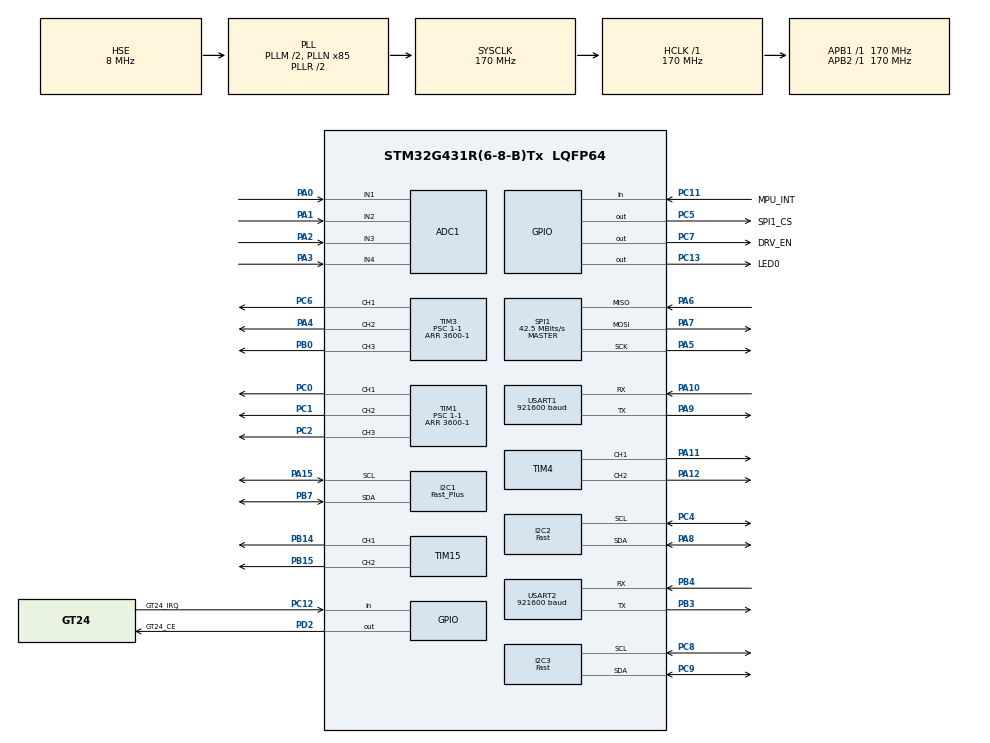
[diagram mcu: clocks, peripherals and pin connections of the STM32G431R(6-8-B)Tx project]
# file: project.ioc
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ADC1.Channel-0\#ChannelRegularConversion=ADC_CHANNEL_1
ADC1.Channel-1\#ChannelRegularConversion=ADC_CHANNEL_2
ADC1.Channel-2\#ChannelRegularConversion=ADC_CHANNEL_3
ADC1.Channel-3\#ChannelRegularConversion=ADC_CHANNEL_4
ADC1.GainCompensation=0
ADC1.NbrOfConversion=4
ADC1.NbrOfConversionFlag=1
ADC1.OffsetNumber-0\#ChannelRegularConversion=ADC_OFFSET_NONE
ADC1.OffsetNumber-1\#ChannelRegularConversion=ADC_OFFSET_NONE
ADC1.OffsetNumber-2\#ChannelRegularConversion=ADC_OFFSET_NONE
ADC1.OffsetNumber-3\#ChannelRegularConversion=ADC_OFFSET_NONE
ADC1.Rank-0\#ChannelRegularConversion=1
ADC1.Rank-1\#ChannelRegularConversion=2
ADC1.Rank-2\#ChannelRegularConversion=3
ADC1.Rank-3\#ChannelRegularConversion=4
ADC1.SamplingTime-0\#ChannelRegularConversion=ADC_SAMPLETIME_2CYCLES_5
ADC1.SamplingTime-1\#ChannelRegularConversion=ADC_SAMPLETIME_2CYCLES_5
ADC1.SamplingTime-2\#ChannelRegularConversion=ADC_SAMPLETIME_2CYCLES_5
ADC1.SamplingTime-3\#ChannelRegularConversion=ADC_SAMPLETIME_2CYCLES_5
ADC1.master=1
Dma.ADC1.0.Direction=DMA_PERIPH_TO_MEMORY
Dma.ADC1.0.EventEnable=DISABLE
Dma.ADC1.0.Instance=DMA1_Channel1
Dma.ADC1.0.MemDataAlignment=DMA_MDATAALIGN_WORD
Dma.ADC1.0.MemInc=DMA_MINC_ENABLE
Dma.ADC1.0.Mode=DMA_CIRCULAR
Dma.ADC1.0.PeriphDataAlignment=DMA_PDATAALIGN_WORD
Dma.ADC1.0.PeriphInc=DMA_PINC_DISABLE
Dma.ADC1.0.Polarity=HAL_DMAMUX_REQ_GEN_RISING
Dma.ADC1.0.Priority=DMA_PRIORITY_LOW
Dma.ADC1.0.RequestNumber=1
Dma.ADC1.0.SignalID=NONE
Dma.ADC1.0.SyncEnable=DISABLE
Dma.ADC1.0.SyncPolarity=HAL_DMAMUX_SYNC_NO_EVENT
Dma.ADC1.0.SyncRequestNumber=1
Dma.ADC1.0.SyncSignalID=NONE
Dma.Request0=ADC1
Dma.Request1=USART1_RX
Dma.Request2=USART1_TX
Dma.Request3=USART2_RX
Dma.Request4=USART2_TX
Dma.USART1_RX.1.Direction=DMA_PERIPH_TO_MEMORY
Dma.USART1_RX.1.EventEnable=DISABLE
Dma.USART1_RX.1.Instance=DMA1_Channel2
Dma.USART1_RX.1.MemDataAlignment=DMA_MDATAALIGN_BYTE
Dma.USART1_RX.1.MemInc=DMA_MINC_ENABLE
Dma.USART1_RX.1.Mode=DMA_NORMAL
Dma.USART1_RX.1.PeriphDataAlignment=DMA_PDATAALIGN_BYTE
Dma.USART1_RX.1.PeriphInc=DMA_PINC_DISABLE
Dma.USART1_RX.1.Polarity=HAL_DMAMUX_REQ_GEN_RISING
Dma.USART1_RX.1.Priority=DMA_PRIORITY_LOW
Dma.USART1_RX.1.RequestNumber=1
Dma.USART1_RX.1.SignalID=NONE
Dma.USART1_RX.1.SyncEnable=DISABLE
Dma.USART1_RX.1.SyncPolarity=HAL_DMAMUX_SYNC_NO_EVENT
Dma.USART1_RX.1.SyncRequestNumber=1
Dma.USART1_RX.1.SyncSignalID=NONE
Dma.USART1_TX.2.Direction=DMA_MEMORY_TO_PERIPH
Dma.USART1_TX.2.EventEnable=DISABLE
Dma.USART1_TX.2.Instance=DMA1_Channel3
Dma.USART1_TX.2.MemDataAlignment=DMA_MDATAALIGN_BYTE
Dma.USART1_TX.2.MemInc=DMA_MINC_ENABLE
Dma.USART1_TX.2.Mode=DMA_NORMAL
Dma.USART1_TX.2.PeriphDataAlignment=DMA_PDATAALIGN_BYTE
Dma.USART1_TX.2.PeriphInc=DMA_PINC_DISABLE
Dma.USART1_TX.2.Polarity=HAL_DMAMUX_REQ_GEN_RISING
Dma.USART1_TX.2.Priority=DMA_PRIORITY_LOW
Dma.USART1_TX.2.RequestNumber=1
Dma.USART1_TX.2.SignalID=NONE
Dma.USART1_TX.2.SyncEnable=DISABLE
Dma.USART1_TX.2.SyncPolarity=HAL_DMAMUX_SYNC_NO_EVENT
Dma.USART1_TX.2.SyncRequestNumber=1
Dma.USART1_TX.2.SyncSignalID=NONE
Dma.USART2_RX.3.Direction=DMA_PERIPH_TO_MEMORY
Dma.USART2_RX.3.EventEnable=DISABLE
Dma.USART2_RX.3.Instance=DMA1_Channel4
Dma.USART2_RX.3.MemDataAlignment=DMA_MDATAALIGN_BYTE
Dma.USART2_RX.3.MemInc=DMA_MINC_ENABLE
Dma.USART2_RX.3.Mode=DMA_NORMAL
Dma.USART2_RX.3.PeriphDataAlignment=DMA_PDATAALIGN_BYTE
Dma.USART2_RX.3.PeriphInc=DMA_PINC_DISABLE
Dma.USART2_RX.3.Polarity=HAL_DMAMUX_REQ_GEN_RISING
Dma.USART2_RX.3.Priority=DMA_PRIORITY_LOW
Dma.USART2_RX.3.RequestNumber=1
Dma.USART2_RX.3.SignalID=NONE
Dma.USART2_RX.3.SyncEnable=DISABLE
Dma.USART2_RX.3.SyncPolarity=HAL_DMAMUX_SYNC_NO_EVENT
Dma.USART2_RX.3.SyncRequestNumber=1
Dma.USART2_RX.3.SyncSignalID=NONE
Dma.USART2_TX.4.Direction=DMA_MEMORY_TO_PERIPH
Dma.USART2_TX.4.EventEnable=DISABLE
Dma.USART2_TX.4.Instance=DMA1_Channel5
Dma.USART2_TX.4.MemDataAlignment=DMA_MDATAALIGN_BYTE
Dma.USART2_TX.4.MemInc=DMA_MINC_ENABLE
Dma.USART2_TX.4.Mode=DMA_NORMAL
Dma.USART2_TX.4.PeriphDataAlignment=DMA_PDATAALIGN_BYTE
Dma.USART2_TX.4.PeriphInc=DMA_PINC_DISABLE
Dma.USART2_TX.4.Polarity=HAL_DMAMUX_REQ_GEN_RISING
Dma.USART2_TX.4.Priority=DMA_PRIORITY_LOW
Dma.USART2_TX.4.RequestNumber=1
Dma.USART2_TX.4.SignalID=NONE
Dma.USART2_TX.4.SyncEnable=DISABLE
Dma.USART2_TX.4.SyncPolarity=HAL_DMAMUX_SYNC_NO_EVENT
Dma.USART2_TX.4.SyncRequestNumber=1
Dma.USART2_TX.4.SyncSignalID=NONE
I2C1.I2C_Speed_Mode=I2C_Fast_Plus
I2C1.Speed=500
I2C1.Timing=0x20820B52
I2C2.I2C_Speed_Mode=I2C_Fast
I2C2.Speed=400
I2C2.Timing=0x40621236
I2C3.I2C_Speed_Mode=I2C_Fast
I2C3.Speed=400
I2C3.Timing=0x40621236
Mcu.Family=STM32G4
Mcu.Name=STM32G431R(6-8-B)Tx
Mcu.Package=LQFP64
Mcu.UserConstants=High_band,460800
NVIC.DMA1_Channel1_IRQn=true\:0\:0\:false\:false\:true\:false\:true\:true
NVIC.DMA1_Channel2_IRQn=true\:0\:0\:false\:false\:true\:false\:true\:true
NVIC.DMA1_Channel3_IRQn=true\:0\:0\:false\:false\:true\:false\:true\:true
NVIC.DMA1_Channel4_IRQn=true\:0\:0\:false\:false\:true\:false\:true\:true
NVIC.DMA1_Channel5_IRQn=true\:0\:0\:false\:false\:true\:false\:true\:true
NVIC.PriorityGroup=NVIC_PRIORITYGROUP_4
NVIC.TIM2_IRQn=true\:3\:0\:true\:false\:true\:true\:true\:true
NVIC.USART1_IRQn=true\:0\:0\:true\:false\:true\:true\:true\:true
NVIC.USART2_IRQn=true\:1\:0\:true\:false\:true\:true\:true\:true
PA0.Mode=IN1-Single-Ended
PA0.Signal=ADC1_IN1
PA1.Mode=IN2-Single-Ended
PA1.Signal=ADC1_IN2
PA10.Mode=Asynchronous
PA10.Signal=USART1_RX
PA11.Signal=S_TIM4_CH1
PA12.Signal=S_TIM4_CH2
PA13.Mode=Serial_Wire
PA13.Signal=SYS_JTMS-SWDIO
PA14.Mode=Serial_Wire
PA14.Signal=SYS_JTCK-SWCLK
PA15.Mode=I2C
PA15.Signal=I2C1_SCL
PA2.Mode=IN3-Single-Ended
PA2.Signal=ADC1_IN3
PA3.Mode=IN4-Single-Ended
PA3.Signal=ADC1_IN4
PA4.Signal=S_TIM3_CH2
PA5.Mode=Full_Duplex_Master
PA5.Signal=SPI1_SCK
PA6.Mode=Full_Duplex_Master
PA6.Signal=SPI1_MISO
PA7.Mode=Full_Duplex_Master
PA7.Signal=SPI1_MOSI
PA8.Mode=I2C
PA8.Signal=I2C2_SDA
PA9.Mode=Asynchronous
PA9.Signal=USART1_TX
PB0.Signal=S_TIM3_CH3
PB14.Signal=S_TIM15_CH1
PB15.Signal=S_TIM15_CH2
PB3.Mode=Asynchronous
PB3.Signal=USART2_TX
PB4.Mode=Asynchronous
PB4.Signal=USART2_RX
PB7.Mode=I2C
PB7.Signal=I2C1_SDA
PC0.Signal=S_TIM1_CH1
PC1.Signal=S_TIM1_CH2
PC11.GPIO_Label=MPU_INT
PC11.Signal=GPIO_Input
PC12.GPIO_Label=GT24_IRQ
PC12.Signal=GPIO_Input
PC13.GPIO_Label=LED0
PC13.PinState=GPIO_PIN_RESET
PC13.Signal=GPIO_Output
PC14-OSC32_IN.Mode=LSE-External-Oscillator
PC14-OSC32_IN.Signal=RCC_OSC32_IN
PC15-OSC32_OUT.Mode=LSE-External-Oscillator
PC15-OSC32_OUT.Signal=RCC_OSC32_OUT
PC2.Signal=S_TIM1_CH3
PC4.Mode=I2C
PC4.Signal=I2C2_SCL
PC5.GPIO_Label=SPI1_CS
PC5.Signal=GPIO_Output
PC6.Signal=S_TIM3_CH1
PC7.GPIO_Label=DRV_EN
PC7.Signal=GPIO_Output
PC8.Mode=I2C
PC8.Signal=I2C3_SCL
PC9.Mode=I2C
PC9.Signal=I2C3_SDA
PD2.GPIO_Label=GT24_CE
PD2.Signal=GPIO_Output
PF0-OSC_IN.Mode=HSE-External-Oscillator
PF0-OSC_IN.Signal=RCC_OSC_IN
PF1-OSC_OUT.Mode=HSE-External-Oscillator
PF1-OSC_OUT.Signal=RCC_OSC_OUT
ProjectManager.HeapSize=0x200
ProjectManager.StackSize=0x400
ProjectManager.TargetToolchain=MDK-ARM V5.32
RCC.ADC12Freq_Value=170000000
RCC.AHBFreq_Value=170000000
RCC.APB1Freq_Value=170000000
RCC.APB1TimFreq_Value=170000000
RCC.APB2Freq_Value=170000000
RCC.APB2TimFreq_Value=170000000
RCC.CortexFreq_Value=170000000
RCC.EXTERNAL_CLOCK_VALUE=12288000
RCC.HCLKFreq_Value=170000000
RCC.HSE_VALUE=8000000
RCC.HSI48_VALUE=48000000
RCC.HSI_VALUE=16000000
RCC.PLLM=RCC_PLLM_DIV2
RCC.PLLN=85
RCC.PLLQ=RCC_PLLQ_DIV6
RCC.PLLSourceVirtual=RCC_PLLSOURCE_HSE
RCC.SYSCLKFreq_VALUE=170000000
RCC.SYSCLKSource=RCC_SYSCLKSOURCE_PLLCLK
RCC.USBFreq_Value=56666666.666666664
RCC.VCOOutputFreq_Value=340000000
SH.S_TIM15_CH1.0=TIM15_CH1,PWM Generation1 CH1
SH.S_TIM15_CH2.0=TIM15_CH2,PWM Generation2 CH2
SH.S_TIM1_CH1.0=TIM1_CH1,PWM Generation1 CH1
SH.S_TIM1_CH2.0=TIM1_CH2,PWM Generation2 CH2
SH.S_TIM1_CH3.0=TIM1_CH3,PWM Generation3 CH3
SH.S_TIM3_CH1.0=TIM3_CH1,PWM Generation1 CH1
SH.S_TIM3_CH2.0=TIM3_CH2,PWM Generation2 CH2
SH.S_TIM3_CH3.0=TIM3_CH3,PWM Generation3 CH3
SH.S_TIM4_CH1.0=TIM4_CH1,PWM Generation1 CH1
SH.S_TIM4_CH2.0=TIM4_CH2,PWM Generation2 CH2
SPI1.BaudRatePrescaler=SPI_BAUDRATEPRESCALER_4
SPI1.CalculateBaudRate=42.5 MBits/s
SPI1.Direction=SPI_DIRECTION_2LINES
SPI1.Mode=SPI_MODE_MASTER
SPI1.VirtualType=VM_MASTER
TIM1.Channel-PWM\ Generation1\ CH1=TIM_CHANNEL_1
TIM1.Channel-PWM\ Generation2\ CH2=TIM_CHANNEL_2
TIM1.Channel-PWM\ Generation3\ CH3=TIM_CHANNEL_3
TIM1.PeriodNoDither=3600-1
TIM1.Prescaler=1-1
TIM1.TIM_MasterOutputTrigger=TIM_TRGO_UPDATE
TIM1.TIM_MasterSlaveMode=TIM_MASTERSLAVEMODE_DISABLE
TIM15.Channel-PWM\ Generation1\ CH1=TIM_CHANNEL_1
TIM15.Channel-PWM\ Generation2\ CH2=TIM_CHANNEL_2
TIM2.PeriodNoDither=100-1
TIM2.Prescaler=1700-1
TIM3.Channel-PWM\ Generation1\ CH1=TIM_CHANNEL_1
TIM3.Channel-PWM\ Generation2\ CH2=TIM_CHANNEL_2
TIM3.Channel-PWM\ Generation3\ CH3=TIM_CHANNEL_3
TIM3.PeriodNoDither=3600-1
TIM3.Prescaler=1-1
TIM4.Channel-PWM\ Generation1\ CH1=TIM_CHANNEL_1
TIM4.Channel-PWM\ Generation2\ CH2=TIM_CHANNEL_2
USART1.BaudRate=921600
USART1.VirtualMode-Asynchronous=VM_ASYNC
USART2.BaudRate=921600
USART2.VirtualMode-Asynchronous=VM_ASYNC
VP_SYS_VS_DBSignals.Mode=DisableDeadBatterySignals
VP_TIM2_VS_ClockSourceINT.Mode=Internal
board=custom

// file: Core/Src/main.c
/* USER CODE BEGIN Header */
/**
  ******************************************************************************
  * @file           : main.c
  * @brief          : Main program body
  ******************************************************************************
  * @attention
  *
  * Copyright (c) 2025 STMicroelectronics.
  * All rights reserved.
  *
  * This software is licensed under terms that can be found in the LICENSE file
  * in the root directory of this software component.
  * If no LICENSE file comes with this software, it is provided AS-IS.
  *
  ******************************************************************************
  */
/* USER CODE END Header */
#include "main.h"
#include "adc.h"
#include "dma.h"
#include "i2c.h"
#include "spi.h"
#include "tim.h"
#include "usart.h"
#include "gpio.h"

/* USER CODE BEGIN Includes */
#include "app.h"
#include "stdio.h"
/* USER CODE END Includes */

void SystemClock_Config(void);

int main(void)
{

  /* MCU Configuration--------------------------------------------------------*/

  /* Reset of all peripherals, Initializes the Flash interface and the Systick. */
  HAL_Init();

  /* Configure the system clock */
  SystemClock_Config();

  /* Initialize all configured peripherals */
  MX_GPIO_Init();
  MX_DMA_Init();
  MX_ADC1_Init();
  MX_SPI1_Init();
  MX_TIM1_Init();
  MX_TIM3_Init();
  MX_TIM4_Init();
  MX_I2C1_Init();
  MX_I2C2_Init();
  MX_I2C3_Init();
  MX_TIM15_Init();
  MX_USART1_UART_Init();
  MX_USART2_UART_Init();
  MX_TIM2_Init();
  /* USER CODE BEGIN 2 */
	app_init();
  /* USER CODE END 2 */

  /* Infinite loop */
  while (1)
  {

  }
}

void SystemClock_Config(void)
{
  RCC_OscInitTypeDef RCC_OscInitStruct = {0};
  RCC_ClkInitTypeDef RCC_ClkInitStruct = {0};

  /** Configure the main internal regulator output voltage
  */
  HAL_PWREx_ControlVoltageScaling(PWR_REGULATOR_VOLTAGE_SCALE1_BOOST);

  /** Initializes the RCC Oscillators according to the specified parameters
  * in the RCC_OscInitTypeDef structure.
  */
  RCC_OscInitStruct.OscillatorType = RCC_OSCILLATORTYPE_HSE;
  RCC_OscInitStruct.HSEState = RCC_HSE_ON;
  RCC_OscInitStruct.PLL.PLLState = RCC_PLL_ON;
  RCC_OscInitStruct.PLL.PLLSource = RCC_PLLSOURCE_HSE;
  RCC_OscInitStruct.PLL.PLLM = RCC_PLLM_DIV2;
  RCC_OscInitStruct.PLL.PLLN = 85;
  RCC_OscInitStruct.PLL.PLLP = RCC_PLLP_DIV2;
  RCC_OscInitStruct.PLL.PLLQ = RCC_PLLQ_DIV6;
  RCC_OscInitStruct.PLL.PLLR = RCC_PLLR_DIV2;
  if (HAL_RCC_OscConfig(&RCC_OscInitStruct) != HAL_OK)
  {
    Error_Handler();
  }

  /** Initializes the CPU, AHB and APB buses clocks
  */
  RCC_ClkInitStruct.ClockType = RCC_CLOCKTYPE_HCLK|RCC_CLOCKTYPE_SYSCLK
                              |RCC_CLOCKTYPE_PCLK1|RCC_CLOCKTYPE_PCLK2;
  RCC_ClkInitStruct.SYSCLKSource = RCC_SYSCLKSOURCE_PLLCLK;
  RCC_ClkInitStruct.AHBCLKDivider = RCC_SYSCLK_DIV1;
  RCC_ClkInitStruct.APB1CLKDivider = RCC_HCLK_DIV1;
  RCC_ClkInitStruct.APB2CLKDivider = RCC_HCLK_DIV1;

  if (HAL_RCC_ClockConfig(&RCC_ClkInitStruct, FLASH_LATENCY_4) != HAL_OK)
  {
    Error_Handler();
  }
}

void Error_Handler(void)
{
  __disable_irq();
  while (1)
  {
  }
}
